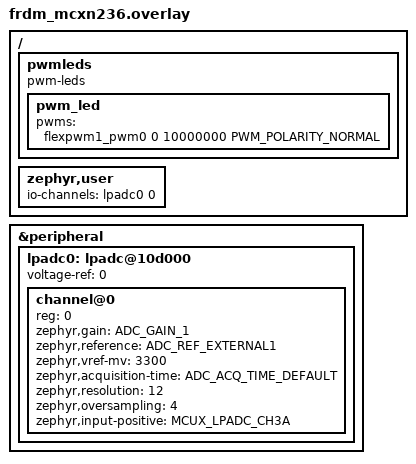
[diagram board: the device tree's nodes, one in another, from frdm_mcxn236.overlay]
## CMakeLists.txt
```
# SPDX-License-Identifier: Apache-2.0

cmake_minimum_required(VERSION 3.20.0)
find_package(Zephyr REQUIRED HINTS $ENV{ZEPHYR_BASE})
project(adc)

target_sources(app PRIVATE src/main.c)
```

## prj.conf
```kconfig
CONFIG_ADC=y
CONFIG_CBPRINTF_FP_SUPPORT=y
CONFIG_PWM=y
CONFIG_LOG=y
```

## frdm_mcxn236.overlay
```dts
#include <zephyr/dt-bindings/adc/adc.h>
#include <zephyr/dt-bindings/adc/mcux-lpadc.h>
#include <zephyr/dt-bindings/pwm/pwm.h>

/ {
    pwmleds {
        compatible = "pwm-leds";
        pwm_led: pwm_led {
            pwms = <&flexpwm1_pwm0 0 10000000 PWM_POLARITY_NORMAL>;
        };
    };
};

/ {
	zephyr,user {
		io-channels = <&lpadc0 0>;
	};
};

&peripheral {
	lpadc0: lpadc@10d000 {
		voltage-ref= <0>;
	};
};

&lpadc0 {
	#address-cells = <1>;
	#size-cells = <0>;

	channel@0 {
		reg = <0>;
		zephyr,gain = "ADC_GAIN_1";
		zephyr,reference = "ADC_REF_EXTERNAL1";
		zephyr,vref-mv = <3300>;
		zephyr,acquisition-time = <ADC_ACQ_TIME_DEFAULT>;
		zephyr,resolution = <12>;
		zephyr,oversampling = <4>;
		zephyr,input-positive = <MCUX_LPADC_CH3A>; /* J4 pin 2 */
	};
};
```

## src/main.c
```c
#include <math.h>
#include <zephyr/drivers/adc.h>
#include <zephyr/drivers/pwm.h>
#include <zephyr/kernel.h>
#include <zephyr/logging/log.h>

LOG_MODULE_REGISTER(Poten_LED);

#define PWM_LED_NODE DT_NODELABEL(pwm_led)
#define PWM_LED_PERIOD DT_PWMS_PERIOD(PWM_LED_NODE)

float floatMap(float x, float in_min, float in_max, float out_min,
               float out_max) {
  return (x - in_min) * (out_max - out_min) / (in_max - in_min) + out_min;
}

int main(void) {
  const struct adc_dt_spec adc_dev = ADC_DT_SPEC_GET(DT_PATH(zephyr_user));
  const struct pwm_dt_spec pwm_led = PWM_DT_SPEC_GET(PWM_LED_NODE);

  if (!adc_is_ready_dt(&adc_dev) || (0 > adc_channel_setup_dt(&adc_dev))) {
    LOG_ERR("TMP device is not ready");
    exit(EXIT_FAILURE);
  }
  if (!pwm_is_ready_dt(&pwm_led)) {
    LOG_ERR("Error: didn't find %s device", DT_NODE_FULL_NAME(PWM_LED_NODE));
    exit(EXIT_FAILURE);
  }

  int16_t value;
  int32_t millivolts;
  float percent;

  struct adc_sequence sequence = {
      .buffer = &value,
      .buffer_size = sizeof(value),
      .calibrate = true,
  };

  while (1) {
    if ((0 != adc_sequence_init_dt(&adc_dev, &sequence)) ||
        (0 != adc_read_dt(&adc_dev, &sequence))) {
      LOG_ERR("TMP ADC failed to read\n");
      exit(EXIT_FAILURE);
    }

    millivolts = value;
    if (0 > adc_raw_to_millivolts_dt(&adc_dev, &millivolts)) {
      LOG_ERR("TMP ADC failed to convert the raw value to millivolts\n");
      exit(EXIT_FAILURE);
    }

    percent = floatMap(millivolts, 0, 3300, 0, 100);
    percent = roundf(percent * 10.0f) / 10.0f;
    millivolts = (int)percent;
    int output = (PWM_LED_PERIOD / 100) * (int)percent;

    if (0 != pwm_set_pulse_dt(&pwm_led, output)) {
      LOG_ERR("Failed to set pulse width");
    }

    printf("%3d%%|PULSE:%8d\n", millivolts, output);
    k_sleep(K_MSEC(50));
  }

  return EXIT_SUCCESS;
}
```
